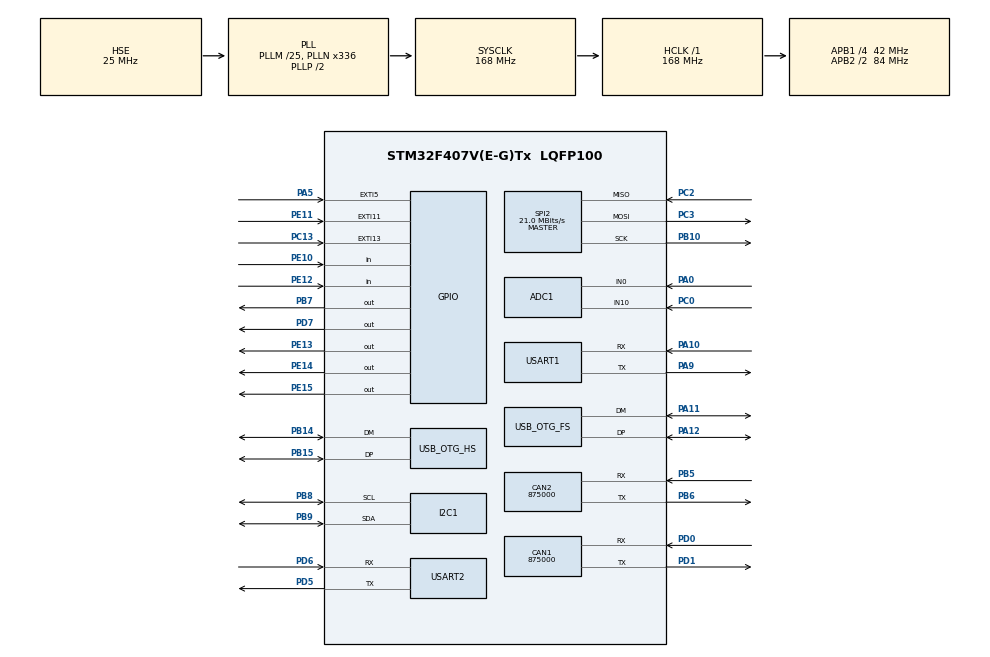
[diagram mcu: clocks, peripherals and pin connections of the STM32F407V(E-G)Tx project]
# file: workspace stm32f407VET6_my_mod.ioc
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ADC1.Channel-4\#ChannelRegularConversion=ADC_CHANNEL_0
ADC1.Channel-6\#ChannelRegularConversion=ADC_CHANNEL_10
ADC1.ContinuousConvMode=ENABLE
ADC1.EOCSelection=ADC_EOC_SEQ_CONV
ADC1.InjNumberOfConversion=0
ADC1.NbrOfConversion=2
ADC1.NbrOfConversionFlag=1
ADC1.Rank-4\#ChannelRegularConversion=1
ADC1.Rank-6\#ChannelRegularConversion=2
ADC1.SamplingTime-4\#ChannelRegularConversion=ADC_SAMPLETIME_3CYCLES
ADC1.SamplingTime-6\#ChannelRegularConversion=ADC_SAMPLETIME_3CYCLES
ADC1.master=1
CAN1.CalculateBaudRate=875000
CAN1.CalculateTimeBit=1142
CAN1.CalculateTimeQuantum=380.95238095238096
CAN2.CalculateBaudRate=875000
CAN2.CalculateTimeBit=1142
CAN2.CalculateTimeQuantum=380.95238095238096
Mcu.Family=STM32F4
Mcu.Name=STM32F407V(E-G)Tx
Mcu.Package=LQFP100
NVIC.EXTI15_10_IRQn=true\:0\:0\:false\:false\:true\:true\:true\:true
NVIC.EXTI9_5_IRQn=true\:0\:0\:false\:false\:true\:true\:true\:true
NVIC.PriorityGroup=NVIC_PRIORITYGROUP_4
NVIC.TIM3_IRQn=true\:0\:0\:false\:false\:true\:true\:true\:true
PA0-WKUP.Signal=ADCx_IN0
PA10.Mode=Asynchronous
PA10.Signal=USART1_RX
PA11.Mode=Device_Only
PA11.Signal=USB_OTG_FS_DM
PA12.Mode=Device_Only
PA12.Signal=USB_OTG_FS_DP
PA13.Mode=JTAG_5_pins
PA13.Signal=SYS_JTMS-SWDIO
PA14.Mode=JTAG_5_pins
PA14.Signal=SYS_JTCK-SWCLK
PA15.Mode=JTAG_5_pins
PA15.Signal=SYS_JTDI
PA5.Signal=GPXTI5
PA9.Mode=Asynchronous
PA9.Signal=USART1_TX
PB10.Mode=Full_Duplex_Master
PB10.Signal=SPI2_SCK
PB14.Mode=Device_Only_FS
PB14.Signal=USB_OTG_HS_DM
PB15.Mode=Device_Only_FS
PB15.Signal=USB_OTG_HS_DP
PB3.Mode=JTAG_5_pins
PB3.Signal=SYS_JTDO-SWO
PB4.Mode=JTAG_5_pins
PB4.Signal=SYS_JTRST
PB5.Mode=CAN_Activate
PB5.Signal=CAN2_RX
PB6.Mode=CAN_Activate
PB6.Signal=CAN2_TX
PB7.Signal=GPIO_Output
PB8.Mode=I2C
PB8.Signal=I2C1_SCL
PB9.Mode=I2C
PB9.Signal=I2C1_SDA
PC0.Signal=ADCx_IN10
PC13-ANTI_TAMP.Signal=GPXTI13
PC14-OSC32_IN.Mode=LSE-External-Oscillator
PC14-OSC32_IN.Signal=RCC_OSC32_IN
PC15-OSC32_OUT.Mode=LSE-External-Oscillator
PC15-OSC32_OUT.Signal=RCC_OSC32_OUT
PC2.Mode=Full_Duplex_Master
PC2.Signal=SPI2_MISO
PC3.Mode=Full_Duplex_Master
PC3.Signal=SPI2_MOSI
PD0.Mode=CAN_Activate
PD0.Signal=CAN1_RX
PD1.Mode=CAN_Activate
PD1.Signal=CAN1_TX
PD5.Mode=Asynchronous
PD5.Signal=USART2_TX
PD6.Mode=Asynchronous
PD6.Signal=USART2_RX
PD7.Signal=GPIO_Output
PE10.Signal=GPIO_Input
PE11.Signal=GPXTI11
PE12.Signal=GPIO_Input
PE13.Signal=GPIO_Output
PE14.Signal=GPIO_Output
PE15.Signal=GPIO_Output
PH0-OSC_IN.Mode=HSE-External-Oscillator
PH0-OSC_IN.Signal=RCC_OSC_IN
PH1-OSC_OUT.Mode=HSE-External-Oscillator
PH1-OSC_OUT.Signal=RCC_OSC_OUT
ProjectManager.HeapSize=0x200
ProjectManager.StackSize=0x400
ProjectManager.TargetToolchain=EWARM V8.50
RCC.48MHZClocksFreq_Value=48000000
RCC.AHBFreq_Value=168000000
RCC.APB1CLKDivider=RCC_HCLK_DIV4
RCC.APB1Freq_Value=42000000
RCC.APB1TimFreq_Value=84000000
RCC.APB2CLKDivider=RCC_HCLK_DIV2
RCC.APB2Freq_Value=84000000
RCC.APB2TimFreq_Value=168000000
RCC.CortexFreq_Value=168000000
RCC.HCLKFreq_Value=168000000
RCC.HSE_VALUE=25000000
RCC.HSI_VALUE=16000000
RCC.PLLM=25
RCC.PLLN=336
RCC.PLLQ=7
RCC.SYSCLKFreq_VALUE=168000000
RCC.SYSCLKSource=RCC_SYSCLKSOURCE_PLLCLK
RCC.VCOOutputFreq_Value=336000000
SH.ADCx_IN0.0=ADC1_IN0,IN0
SH.ADCx_IN10.0=ADC1_IN10,IN10
SPI2.CalculateBaudRate=21.0 MBits/s
SPI2.Direction=SPI_DIRECTION_2LINES
SPI2.Mode=SPI_MODE_MASTER
SPI2.VirtualType=VM_MASTER
TIM3.Period=839
TIM3.TIM_MasterOutputTrigger=TIM_TRGO_UPDATE
USART1.VirtualMode=VM_ASYNC
USART2.VirtualMode=VM_ASYNC
USB_OTG_FS.VirtualMode=Device_Only
USB_OTG_HS.VirtualMode-Device_Only_FS=Device_Only_FS
VP_RTC_VS_RTC_Activate.Mode=RTC_Enabled
VP_TIM3_VS_ClockSourceINT.Mode=Internal
board=custom

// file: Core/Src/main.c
/* USER CODE BEGIN Header */
/**
  ******************************************************************************
  * @file           : main.c
  * @brief          : Main program body
  ******************************************************************************
  * @attention
  *
  * Copyright (c) 2025 STMicroelectronics.
  * All rights reserved.
  *
  * This software is licensed under terms that can be found in the LICENSE file
  * in the root directory of this software component.
  * If no LICENSE file comes with this software, it is provided AS-IS.
  *
  ******************************************************************************
  */

/**
Проект предназначен для платы APM32F407VET6 с китая
На PORT A5 подется 100 Гц
Ловим триггером по положительному фронту,
PORT B7 выплевываем стробу, но стробу можно отслеживать начало и конец
**/
/* USER CODE END Header */
#include "main.h"
#include "adc.h"
#include "can.h"
#include "i2c.h"
#include "rtc.h"
#include "spi.h"
#include "tim.h"
#include "usart.h"
#include "usb_otg.h"
#include "gpio.h"

void SystemClock_Config(void);

/* USER CODE BEGIN 0 */
//HAL_TIM_Base_Start_IT(&htim3);
uint8_t a;//тестовая переменная
extern uint32_t timer3;//вызов переменной из файла stm32f4xx_it.c
/* USER CODE END 0 */

int main(void)
{
  /* USER CODE BEGIN 1 */

  a=0;
  /* USER CODE END 1 */

  /* MCU Configuration--------------------------------------------------------*/

  /* Reset of all peripherals, Initializes the Flash interface and the Systick. */
  HAL_Init();

  /* Configure the system clock */
  SystemClock_Config();

  /* Initialize all configured peripherals */
  MX_GPIO_Init();
  MX_CAN1_Init();
  MX_CAN2_Init();
  MX_I2C1_Init();
  MX_RTC_Init();
  MX_SPI2_Init();
  MX_USART1_UART_Init();
  MX_USART2_UART_Init();
  MX_USB_OTG_FS_PCD_Init();
  MX_USB_OTG_HS_PCD_Init();
  MX_ADC1_Init();
  MX_TIM3_Init();
  /* USER CODE BEGIN 2 */
  HAL_TIM_Base_Start_IT(&htim3);//обязательно вызывать старт, инначе не будет работать TIM3
  HAL_GPIO_WritePin(GPIOE, GPIO_PIN_14, GPIO_PIN_SET);
  HAL_GPIO_WritePin(GPIOE, GPIO_PIN_15, GPIO_PIN_SET);
  /* USER CODE END 2 */

  /* Infinite loop */
  while (1)
  {

  }
}

void SystemClock_Config(void)
{
  RCC_OscInitTypeDef RCC_OscInitStruct = {0};
  RCC_ClkInitTypeDef RCC_ClkInitStruct = {0};

  /** Configure the main internal regulator output voltage
  */
  __HAL_RCC_PWR_CLK_ENABLE();
  __HAL_PWR_VOLTAGESCALING_CONFIG(PWR_REGULATOR_VOLTAGE_SCALE1);

  /** Initializes the RCC Oscillators according to the specified parameters
  * in the RCC_OscInitTypeDef structure.
  */
  RCC_OscInitStruct.OscillatorType = RCC_OSCILLATORTYPE_LSI|RCC_OSCILLATORTYPE_HSE;
  RCC_OscInitStruct.HSEState = RCC_HSE_ON;
  RCC_OscInitStruct.LSIState = RCC_LSI_ON;
  RCC_OscInitStruct.PLL.PLLState = RCC_PLL_ON;
  RCC_OscInitStruct.PLL.PLLSource = RCC_PLLSOURCE_HSE;
  RCC_OscInitStruct.PLL.PLLM = 25;
  RCC_OscInitStruct.PLL.PLLN = 336;
  RCC_OscInitStruct.PLL.PLLP = RCC_PLLP_DIV2;
  RCC_OscInitStruct.PLL.PLLQ = 7;
  if (HAL_RCC_OscConfig(&RCC_OscInitStruct) != HAL_OK)
  {
    Error_Handler();
  }

  /** Initializes the CPU, AHB and APB buses clocks
  */
  RCC_ClkInitStruct.ClockType = RCC_CLOCKTYPE_HCLK|RCC_CLOCKTYPE_SYSCLK
                              |RCC_CLOCKTYPE_PCLK1|RCC_CLOCKTYPE_PCLK2;
  RCC_ClkInitStruct.SYSCLKSource = RCC_SYSCLKSOURCE_PLLCLK;
  RCC_ClkInitStruct.AHBCLKDivider = RCC_SYSCLK_DIV1;
  RCC_ClkInitStruct.APB1CLKDivider = RCC_HCLK_DIV4;
  RCC_ClkInitStruct.APB2CLKDivider = RCC_HCLK_DIV2;

  if (HAL_RCC_ClockConfig(&RCC_ClkInitStruct, FLASH_LATENCY_5) != HAL_OK)
  {
    Error_Handler();
  }
}

void Error_Handler(void)
{
  __disable_irq();
  while (1)
  {
  }
}
